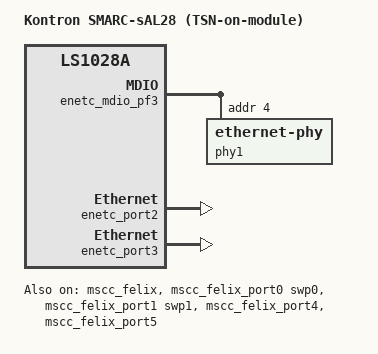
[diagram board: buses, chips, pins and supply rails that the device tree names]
/dts-v1/;
#include "fsl-ls1028a-kontron-sl28.dts"
/ {
	model = "Kontron SMARC-sAL28 (TSN-on-module)";
	compatible = "kontron,sl28-var2", "kontron,sl28", "fsl,ls1028a";
};
&enetc_mdio_pf3 {
	phy1: ethernet-phy@4 {
		reg = <0x4>;
		eee-broken-1000t;
		eee-broken-100tx;
	};
};
&enetc_port0 {
	status = "disabled";
	/delete-property/ phy-handle;
};
&enetc_port2 {
	nvmem-cells = <&base_mac_address 2>;
	nvmem-cell-names = "mac-address";
	status = "okay";
};
&enetc_port3 {
	nvmem-cells = <&base_mac_address 3>;
	nvmem-cell-names = "mac-address";
	status = "okay";
};
&mscc_felix {
	status = "okay";
};
&mscc_felix_port0 {
	label = "swp0";
	managed = "in-band-status";
	phy-handle = <&phy0>;
	phy-mode = "sgmii";
	nvmem-cells = <&base_mac_address 0>;
	nvmem-cell-names = "mac-address";
	status = "okay";
};
&mscc_felix_port1 {
	label = "swp1";
	managed = "in-band-status";
	phy-handle = <&phy1>;
	phy-mode = "sgmii";
	nvmem-cells = <&base_mac_address 1>;
	nvmem-cell-names = "mac-address";
	status = "okay";
};
&mscc_felix_port4 {
	status = "okay";
};
&mscc_felix_port5 {
	status = "okay";
};
